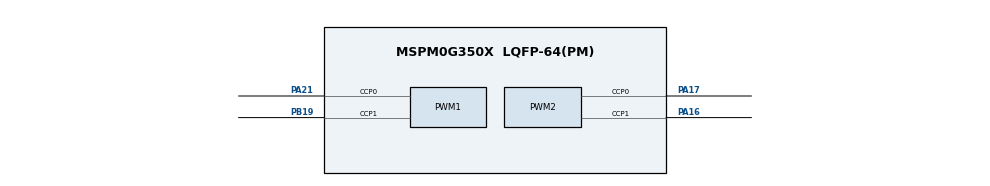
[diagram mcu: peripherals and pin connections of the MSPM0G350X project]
/**
 * @cliArgs --device "MSPM0G350X" --part "Default" --package "LQFP-64(PM)" --product "mspm0_sdk@2.02.00.05"
 * @versions {"tool":"1.21.1+3772"}
 */

/**
 * Import the modules used in this configuration.
 */
const GPIO   = scripting.addModule("/ti/driverlib/GPIO", {}, false);
const GPIO1  = GPIO.addInstance();
const GPIO2  = GPIO.addInstance();
const GPIO3  = GPIO.addInstance();
const GPIO4  = GPIO.addInstance();
const GPIO5  = GPIO.addInstance();
const GPIO6  = GPIO.addInstance();
const I2C    = scripting.addModule("/ti/driverlib/I2C", {}, false);
const I2C1   = I2C.addInstance();
const PWM    = scripting.addModule("/ti/driverlib/PWM", {}, false);
const PWM1   = PWM.addInstance();
const PWM2   = PWM.addInstance();
const SYSCTL = scripting.addModule("/ti/driverlib/SYSCTL");
const TIMER  = scripting.addModule("/ti/driverlib/TIMER", {}, false);
const TIMER1 = TIMER.addInstance();
const UART   = scripting.addModule("/ti/driverlib/UART", {}, false);
const UART1  = UART.addInstance();

/**
 * Write custom configuration values to the imported modules.
 */
const gate7  = system.clockTree["MFCLKGATE"];
gate7.enable = true;

GPIO1.$name                              = "LED1";
GPIO1.port                               = "PORTB";
GPIO1.associatedPins[0].$name            = "PIN_22";
GPIO1.associatedPins[0].internalResistor = "PULL_DOWN";
GPIO1.associatedPins[0].assignedPin      = "22";

const Board = scripting.addModule("/ti/driverlib/Board", {}, false);

GPIO2.$name                              = "KEY";
GPIO2.port                               = "PORTB";
GPIO2.associatedPins[0].$name            = "PIN_21";
GPIO2.associatedPins[0].direction        = "INPUT";
GPIO2.associatedPins[0].internalResistor = "PULL_UP";
GPIO2.associatedPins[0].assignedPin      = "21";

GPIO3.$name                          = "TB6612";
GPIO3.port                           = "PORTA";
GPIO3.associatedPins.create(4);
GPIO3.associatedPins[0].$name        = "AIN1";
GPIO3.associatedPins[0].initialValue = "SET";
GPIO3.associatedPins[0].assignedPin  = "14";
GPIO3.associatedPins[1].$name        = "AIN2";
GPIO3.associatedPins[1].initialValue = "SET";
GPIO3.associatedPins[1].assignedPin  = "15";
GPIO3.associatedPins[2].$name        = "BIN1";
GPIO3.associatedPins[2].initialValue = "SET";
GPIO3.associatedPins[2].assignedPin  = "12";
GPIO3.associatedPins[3].$name        = "BIN2";
GPIO3.associatedPins[3].initialValue = "SET";
GPIO3.associatedPins[3].assignedPin  = "13";

GPIO4.$name                          = "Track";
GPIO4.associatedPins.create(8);
GPIO4.associatedPins[0].$name        = "DO";
GPIO4.associatedPins[0].direction    = "INPUT";
GPIO4.associatedPins[0].assignedPort = "PORTA";
GPIO4.associatedPins[0].assignedPin  = "24";
GPIO4.associatedPins[1].$name        = "D1";
GPIO4.associatedPins[1].direction    = "INPUT";
GPIO4.associatedPins[1].assignedPort = "PORTA";
GPIO4.associatedPins[1].assignedPin  = "25";
GPIO4.associatedPins[2].$name        = "D2";
GPIO4.associatedPins[2].direction    = "INPUT";
GPIO4.associatedPins[2].assignedPort = "PORTA";
GPIO4.associatedPins[2].assignedPin  = "26";
GPIO4.associatedPins[3].$name        = "D3";
GPIO4.associatedPins[3].direction    = "INPUT";
GPIO4.associatedPins[3].assignedPort = "PORTA";
GPIO4.associatedPins[3].assignedPin  = "27";
GPIO4.associatedPins[4].$name        = "D4";
GPIO4.associatedPins[4].direction    = "INPUT";
GPIO4.associatedPins[4].assignedPort = "PORTA";
GPIO4.associatedPins[4].assignedPin  = "28";
GPIO4.associatedPins[5].$name        = "D5";
GPIO4.associatedPins[5].direction    = "INPUT";
GPIO4.associatedPins[5].assignedPort = "PORTA";
GPIO4.associatedPins[5].assignedPin  = "29";
GPIO4.associatedPins[6].$name        = "D6";
GPIO4.associatedPins[6].direction    = "INPUT";
GPIO4.associatedPins[6].assignedPort = "PORTA";
GPIO4.associatedPins[6].assignedPin  = "30";
GPIO4.associatedPins[7].$name        = "D7";
GPIO4.associatedPins[7].direction    = "INPUT";
GPIO4.associatedPins[7].assignedPort = "PORTA";
GPIO4.associatedPins[7].assignedPin  = "31";

GPIO5.$name                               = "ENCODERA";
GPIO5.associatedPins.create(2);
GPIO5.associatedPins[0].$name             = "E1A";
GPIO5.associatedPins[0].direction         = "INPUT";
GPIO5.associatedPins[0].interruptEn       = true;
GPIO5.associatedPins[0].polarity          = "RISE";
GPIO5.associatedPins[0].interruptPriority = "1";
GPIO5.associatedPins[1].$name             = "E1B";
GPIO5.associatedPins[1].direction         = "INPUT";
GPIO5.associatedPins[1].interruptEn       = true;
GPIO5.associatedPins[1].polarity          = "RISE";
GPIO5.associatedPins[1].interruptPriority = "1";

GPIO6.$name                               = "ENCODERB";
GPIO6.associatedPins.create(2);
GPIO6.associatedPins[0].direction         = "INPUT";
GPIO6.associatedPins[0].interruptEn       = true;
GPIO6.associatedPins[0].polarity          = "RISE";
GPIO6.associatedPins[0].$name             = "E2A";
GPIO6.associatedPins[0].interruptPriority = "1";
GPIO6.associatedPins[1].direction         = "INPUT";
GPIO6.associatedPins[1].interruptEn       = true;
GPIO6.associatedPins[1].polarity          = "RISE";
GPIO6.associatedPins[1].$name             = "E2B";
GPIO6.associatedPins[1].interruptPriority = "1";

I2C1.$name                             = "I2C_OLED";
I2C1.basicEnableController             = true;
I2C1.basicControllerStandardBusSpeed   = "Fast";
I2C1.sdaPinConfig.$name                = "ti_driverlib_gpio_GPIOPinGeneric0";
I2C1.sdaPinConfig.hideOutputInversion  = scripting.forceWrite(false);
I2C1.sdaPinConfig.onlyInternalResistor = scripting.forceWrite(false);
I2C1.sdaPinConfig.passedPeripheralType = scripting.forceWrite("Digital");
I2C1.sclPinConfig.$name                = "ti_driverlib_gpio_GPIOPinGeneric1";
I2C1.sclPinConfig.hideOutputInversion  = scripting.forceWrite(false);
I2C1.sclPinConfig.onlyInternalResistor = scripting.forceWrite(false);
I2C1.sclPinConfig.passedPeripheralType = scripting.forceWrite("Digital");

PWM1.$name                              = "PWM_SERVO";
PWM1.clockDivider                       = 8;
PWM1.timerCount                         = 2000;
PWM1.clockPrescale                      = 40;
PWM1.timerStartTimer                    = true;
PWM1.peripheral.$assign                 = "TIMG8";
PWM1.peripheral.ccp0Pin.$assign         = "PA21";
PWM1.peripheral.ccp1Pin.$assign         = "PB19";
PWM1.PWM_CHANNEL_0.$name                = "ti_driverlib_pwm_PWMTimerCC0";
PWM1.PWM_CHANNEL_1.$name                = "ti_driverlib_pwm_PWMTimerCC1";
PWM1.ccp0PinConfig.$name                = "ti_driverlib_gpio_GPIOPinGeneric4";
PWM1.ccp0PinConfig.direction            = scripting.forceWrite("OUTPUT");
PWM1.ccp0PinConfig.hideOutputInversion  = scripting.forceWrite(false);
PWM1.ccp0PinConfig.onlyInternalResistor = scripting.forceWrite(false);
PWM1.ccp0PinConfig.passedPeripheralType = scripting.forceWrite("Digital");
PWM1.ccp1PinConfig.$name                = "ti_driverlib_gpio_GPIOPinGeneric5";
PWM1.ccp1PinConfig.direction            = scripting.forceWrite("OUTPUT");
PWM1.ccp1PinConfig.hideOutputInversion  = scripting.forceWrite(false);
PWM1.ccp1PinConfig.onlyInternalResistor = scripting.forceWrite(false);
PWM1.ccp1PinConfig.passedPeripheralType = scripting.forceWrite("Digital");

PWM2.$name                              = "PWM_MOTOR";
PWM2.timerCount                         = 10000;
PWM2.clockDivider                       = 4;
PWM2.timerStartTimer                    = true;
PWM2.peripheral.$assign                 = "TIMA1";
PWM2.peripheral.ccp0Pin.$assign         = "PA17";
PWM2.peripheral.ccp1Pin.$assign         = "PA16";
PWM2.PWM_CHANNEL_0.$name                = "ti_driverlib_pwm_PWMTimerCC2";
PWM2.PWM_CHANNEL_0.invert               = true;
PWM2.PWM_CHANNEL_1.$name                = "ti_driverlib_pwm_PWMTimerCC3";
PWM2.PWM_CHANNEL_1.invert               = true;
PWM2.ccp0PinConfig.$name                = "ti_driverlib_gpio_GPIOPinGeneric6";
PWM2.ccp0PinConfig.direction            = scripting.forceWrite("OUTPUT");
PWM2.ccp0PinConfig.hideOutputInversion  = scripting.forceWrite(false);
PWM2.ccp0PinConfig.onlyInternalResistor = scripting.forceWrite(false);
PWM2.ccp0PinConfig.passedPeripheralType = scripting.forceWrite("Digital");
PWM2.ccp1PinConfig.$name                = "ti_driverlib_gpio_GPIOPinGeneric7";
PWM2.ccp1PinConfig.direction            = scripting.forceWrite("OUTPUT");
PWM2.ccp1PinConfig.hideOutputInversion  = scripting.forceWrite(false);
PWM2.ccp1PinConfig.onlyInternalResistor = scripting.forceWrite(false);
PWM2.ccp1PinConfig.passedPeripheralType = scripting.forceWrite("Digital");

SYSCTL.forceDefaultClkConfig = true;
SYSCTL.clockTreeEn           = true;

TIMER1.$name              = "TIMER_0";
TIMER1.timerMode          = "PERIODIC";
TIMER1.timerStartTimer    = true;
TIMER1.timerClkDiv        = 8;
TIMER1.interrupts         = ["ZERO"];
TIMER1.interruptPriority  = "2";
TIMER1.timerPeriod        = "10 ms";
TIMER1.peripheral.$assign = "TIMG0";

UART1.$name             = "UART_0";
UART1.uartClkDiv        = "8";
UART1.targetBaudRate    = 115200;
UART1.enabledInterrupts = ["RX"];
UART1.txPinConfig.$name = "ti_driverlib_gpio_GPIOPinGeneric2";
UART1.rxPinConfig.$name = "ti_driverlib_gpio_GPIOPinGeneric3";

/**
 * Pinmux solution for unlocked pins/peripherals. This ensures that minor changes to the automatic solver in a future
 * version of the tool will not impact the pinmux you originally saw.  These lines can be completely deleted in order to
 * re-solve from scratch.
 */
GPIO1.associatedPins[0].pin.$suggestSolution = "PB22";
Board.peripheral.$suggestSolution            = "DEBUGSS";
Board.peripheral.swclkPin.$suggestSolution   = "PA20";
Board.peripheral.swdioPin.$suggestSolution   = "PA19";
GPIO2.associatedPins[0].pin.$suggestSolution = "PB21";
GPIO3.associatedPins[0].pin.$suggestSolution = "PA14";
GPIO3.associatedPins[1].pin.$suggestSolution = "PA15";
GPIO3.associatedPins[2].pin.$suggestSolution = "PA12";
GPIO3.associatedPins[3].pin.$suggestSolution = "PA13";
GPIO4.associatedPins[0].pin.$suggestSolution = "PA24";
GPIO4.associatedPins[1].pin.$suggestSolution = "PA25";
GPIO4.associatedPins[2].pin.$suggestSolution = "PA26";
GPIO4.associatedPins[3].pin.$suggestSolution = "PA27";
GPIO4.associatedPins[4].pin.$suggestSolution = "PA28";
GPIO4.associatedPins[5].pin.$suggestSolution = "PA29";
GPIO4.associatedPins[6].pin.$suggestSolution = "PA30";
GPIO4.associatedPins[7].pin.$suggestSolution = "PA31";
GPIO5.associatedPins[0].pin.$suggestSolution = "PB13";
GPIO5.associatedPins[1].pin.$suggestSolution = "PB14";
GPIO6.associatedPins[0].pin.$suggestSolution = "PB15";
GPIO6.associatedPins[1].pin.$suggestSolution = "PB16";
I2C1.peripheral.$suggestSolution             = "I2C0";
I2C1.peripheral.sdaPin.$suggestSolution      = "PA0";
I2C1.peripheral.sclPin.$suggestSolution      = "PA1";
UART1.peripheral.$suggestSolution            = "UART0";
UART1.peripheral.rxPin.$suggestSolution      = "PA11";
UART1.peripheral.txPin.$suggestSolution      = "PA10";
